# ATSAML21E17B register map
Vendor: Atmel Corporation; Series: SAML21; File version: B
CPU: CM0+ r0p1, little endian, no MPU, no FPU, VTOR, 2 interrupt priority bits
Registers are 32-bit, read-write, reset 0x0 unless marked. A register's access mark holds for its fields unless they carry their own. Offsets are from the block's base; [hi:lo] are bit positions; {n}, {i} and the like mark numbered series; 'fields as' and 'values as' point back to an identical list.

## CCL — Configurable Custom Logic
Base 0x43001C00; register names take the prefix CCL_
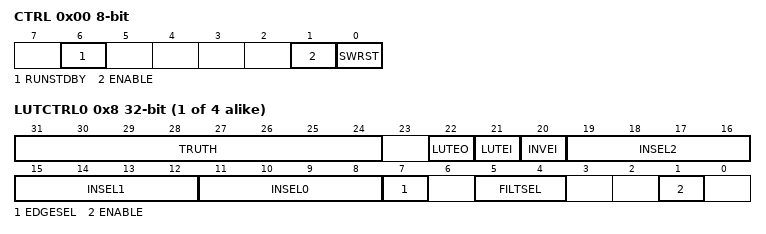
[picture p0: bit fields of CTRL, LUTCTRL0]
0x00 CTRL 8-bit — Control
  [6] RUNSTDBY — Run during Standby
  [1] ENABLE
  [0] SWRST wo — Software Reset
{0x4+i} SEQCTRL{i} (i=0..1) 8-bit — SEQ Control x
  [3:0] SEQSEL — Sequential Selection
    0=DISABLE (Sequential logic is disabled); 1=DFF (D flip flop); 2=JK (JK flip flop); 3=LATCH (D latch); 4=RS (RS latch)
{0x8+4i} LUTCTRL{i} (i=0..3) — LUT Control x
  [31:24] TRUTH — Truth Value
  [22] LUTEO — Event Output Enable
  [21] LUTEI — Event Input Enable
  [20] INVEI — Input Event Invert
  [19:16] INSEL2 — Input Selection 2
  [15:12] INSEL1 — Input Selection 1
  [11:8] INSEL0 — Input Selection 0
    0=MASK (Masked input); 1=FEEDBACK (Feedback input source); 2=LINK (Linked LUT input source); 3=EVENT (Event in put source); 4=IO (I/O pin input source); 5=AC (AC input source); 6=TC (TC input source); 7=ALTTC (Alternate TC input source); 8=TCC (TCC input source); 9=SERCOM (SERCOM inout source)
  [7] EDGESEL — Edge Selection
  [5:4] FILTSEL — Filter Selection
    0=DISABLE (Filter disabled); 1=SYNCH (Synchronizer enabled); 2=FILTER (Filter enabled)
  [1] ENABLE — LUT Enable

## DAC — Digital-to-Analog Converter
Base 0x42003000; register names take the prefix DAC_
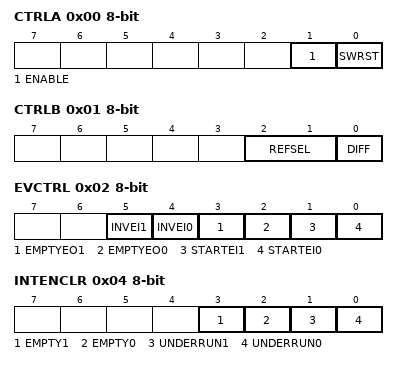
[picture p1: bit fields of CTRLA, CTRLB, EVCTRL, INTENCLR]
0x00 CTRLA 8-bit — Control A
  [1] ENABLE — Enable DAC Controller
  [0] SWRST — Software Reset
0x01 CTRLB 8-bit — Control B
  [2:1] REFSEL — Reference Selection for DAC0/1
    0=VREFPU (External reference unbuffered); 1=VDDANA (Analog supply); 2=VREFPB (External reference buffered); 3=INTREF (Internal bandgap reference)
  [0] DIFF — Differential mode enable
0x02 EVCTRL 8-bit — Event Control
  [5] INVEI1 — Enable Invertion of DAC 1 input event
  [4] INVEI0 — Enable Invertion of DAC 0 input event
  [3] EMPTYEO1 — Data Buffer Empty Event Output DAC 1
  [2] EMPTYEO0 — Data Buffer Empty Event Output DAC 0
  [1] STARTEI1 — Start Conversion Event Input DAC 1
  [0] STARTEI0 — Start Conversion Event Input DAC 0
0x04 INTENCLR 8-bit — Interrupt Enable Clear
  [3] EMPTY1 — Data Buffer 1 Empty Interrupt Enable
  [2] EMPTY0 — Data Buffer 0 Empty Interrupt Enable
  [1] UNDERRUN1 — Underrun Interrupt Enable for DAC 1
  [0] UNDERRUN0 — Underrun Interrupt Enable for DAC 0
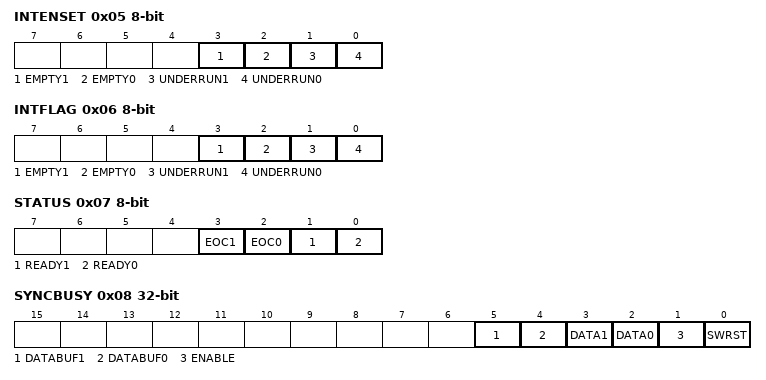
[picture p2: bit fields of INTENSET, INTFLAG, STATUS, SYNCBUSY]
0x05 INTENSET 8-bit — Interrupt Enable Set
  fields as INTENCLR
0x06 INTFLAG 8-bit — Interrupt Flag Status and Clear
  [3] EMPTY1 — Data Buffer 1 Empty
  [2] EMPTY0 — Data Buffer 0 Empty
  [1] UNDERRUN1 — DAC 1 Underrun
  [0] UNDERRUN0 — DAC 0 Underrun
0x07 STATUS 8-bit ro
  [3] EOC1 — DAC 1 End of Conversion
  [2] EOC0 — DAC 0 End of Conversion
  [1] READY1 — DAC 1 Startup Ready
  [0] READY0 — DAC 0 Startup Ready
0x08 SYNCBUSY ro — Synchronization Busy
  [5] DATABUF1 — Data Buffer DAC 1
  [4] DATABUF0 — Data Buffer DAC 0
  [3] DATA1 — Data DAC 1
  [2] DATA0 — Data DAC 0
  [1] ENABLE — DAC Enable Status
  [0] SWRST — Software Reset
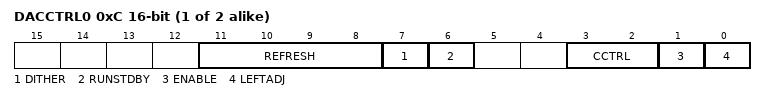
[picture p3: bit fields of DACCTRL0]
{0xC+2i} DACCTRL{i} (i=0..1) 16-bit — DAC n Control
  [11:8] REFRESH — Refresh period
  [7] DITHER — Dithering Mode
  [6] RUNSTDBY — Run in Standby
  [3:2] CCTRL — Current Control
    0=CC12M (1MHz<GCLK_DAC<12MHz); 1=CC1M (100kHz<GCLK_DAC<1MHz); 2=CC100K (10kHz<GCLK_DAC<100kHz); 3=CC10K (GCLK_DAC<100kHz)
  [1] ENABLE — Enable DAC0
  [0] LEFTADJ — Left Adjusted Data
{0x10+2i} DATA{i} (i=0..1) 16-bit wo — DAC n Data
  [15:0] DATA — DAC0 Data
{0x14+2i} DATABUF{i} (i=0..1) 16-bit wo — DAC n Data Buffer
  [15:0] DATABUF — DAC0 Data Buffer
0x18 DBGCTRL 8-bit — Debug Control
  [0] DBGRUN — Debug Run

## DSU — Device Service Unit
Base 0x41002000; register names take the prefix DSU_
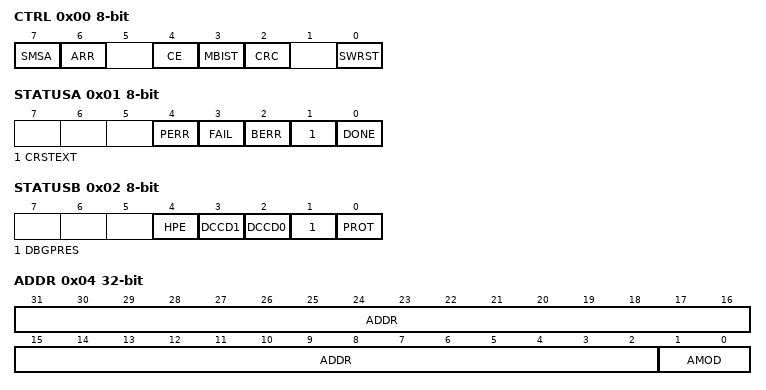
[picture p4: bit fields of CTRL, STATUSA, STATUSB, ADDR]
0x00 CTRL 8-bit wo — Control
  [7] SMSA — Start Memory Stream Access
  [6] ARR — Auxiliary Row Read
  [4] CE — Chip-Erase
  [3] MBIST — Memory built-in self-test
  [2] CRC — 32-bit Cyclic Redundancy Code
  [0] SWRST — Software Reset
0x01 STATUSA 8-bit
  [4] PERR — Protection Error
  [3] FAIL — Failure
  [2] BERR — Bus Error
  [1] CRSTEXT — CPU Reset Phase Extension
  [0] DONE
0x02 STATUSB 8-bit ro
  [4] HPE — Hot-Plugging Enable
  [3] DCCD1 — Debug Communication Channel 1 Dirty
  [2] DCCD0 — Debug Communication Channel 0 Dirty
  [1] DBGPRES — Debugger Present
  [0] PROT — Protected
0x04 ADDR — Address
  [31:2] ADDR — Address
  [1:0] AMOD — Access Mode
0x08 LENGTH
  [31:2] LENGTH
0x0C DATA
{0x10+4i} DCC{i} (i=0..1) — Debug Communication Channel n
  [31:0] DATA
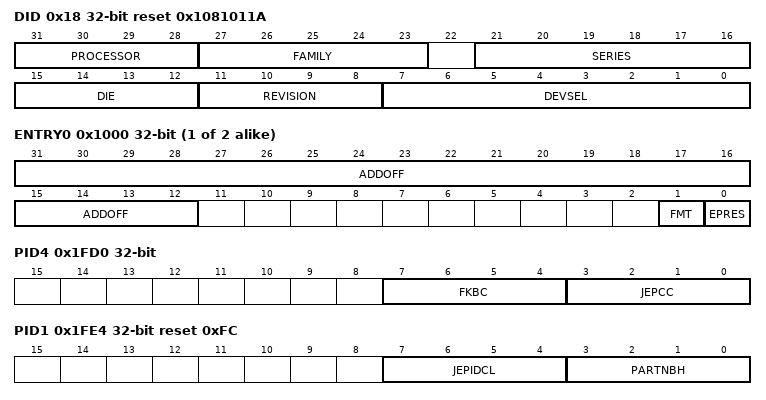
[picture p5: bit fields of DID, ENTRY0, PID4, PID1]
0x18 DID ro reset 0x1081011A — Device Identification
  [31:28] PROCESSOR
    0=Cortex-M0; 1=Cortex-M0+; 2=Cortex-M3; 3=Cortex-M4
  [27:23] FAMILY
    0=General purpose microcontroller; 1=PicoPower
  [21:16] SERIES
    0=Cortex-M0+ processor, basic feature set; 1=Cortex-M0+ processor, USB
  [15:12] DIE — Die Number
  [11:8] REVISION — Revision Number
  [7:0] DEVSEL — Device Select
{0xF0+4i} DCFG{i} (i=0..1) — Device Configuration
  [31:0] DCFG
{0x1000+4i} ENTRY{i} (i=0..1) ro — Coresight ROM Table Entry n
  [31:12] ADDOFF — Address Offset
  [1] FMT — Format
  [0] EPRES — Entry Present
0x1008 END ro — Coresight ROM Table End
  [31:0] END — End Marker
0x1FCC MEMTYPE ro — Coresight ROM Table Memory Type
  [0] SMEMP — System Memory Present
0x1FD0 PID4 ro — Peripheral Identification 4
  [7:4] FKBC — 4KB count
  [3:0] JEPCC — JEP-106 Continuation Code
{0x1FC0+4i} PID{i} ro (i=5..7) — Peripheral Identification {i}
0x1FE0 PID0 ro — Peripheral Identification 0
  [7:0] PARTNBL — Part Number Low
0x1FE4 PID1 ro reset 0xFC — Peripheral Identification 1
  [7:4] JEPIDCL — Low part of the JEP-106 Identity Code
  [3:0] PARTNBH — Part Number High
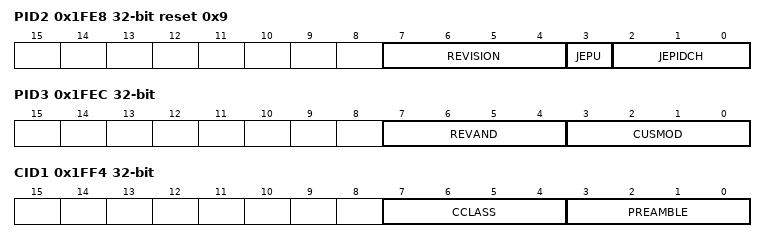
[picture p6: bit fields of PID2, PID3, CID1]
0x1FE8 PID2 ro reset 0x9 — Peripheral Identification 2
  [7:4] REVISION — Revision Number
  [3] JEPU — JEP-106 Identity Code is used
  [2:0] JEPIDCH — JEP-106 Identity Code High
0x1FEC PID3 ro — Peripheral Identification 3
  [7:4] REVAND — Revision Number
  [3:0] CUSMOD — ARM CUSMOD
0x1FF0 CID0 ro — Component Identification 0
  [7:0] PREAMBLEB0 — Preamble Byte 0
0x1FF4 CID1 ro — Component Identification 1
  [7:4] CCLASS — Component Class
  [3:0] PREAMBLE
0x1FF8 CID2 ro — Component Identification 2
  [7:0] PREAMBLEB2 — Preamble Byte 2
0x1FFC CID3 ro — Component Identification 3
  [7:0] PREAMBLEB3 — Preamble Byte 3

## Notices in the file
Atmel Microcontroller Software Support
Copyright (c) 2015, Atmel Corporation
All rights reserved.
Redistribution and use in source and binary forms, with or without
modification, are permitted provided that the following condition is met:
- Redistributions of source code must retain the above copyright notice,
this list of conditions and the disclaimer below.
Atmel's name may not be used to endorse or promote products derived from
this software without specific prior written permission.
DISCLAIMER: THIS SOFTWARE IS PROVIDED BY ATMEL "AS IS" AND ANY EXPRESS OR
IMPLIED WARRANTIES, INCLUDING, BUT NOT LIMITED TO, THE IMPLIED WARRANTIES OF
MERCHANTABILITY, FITNESS FOR A PARTICULAR PURPOSE AND NON-INFRINGEMENT ARE
DISCLAIMED. IN NO EVENT SHALL ATMEL BE LIABLE FOR ANY DIRECT, INDIRECT,
INCIDENTAL, SPECIAL, EXEMPLARY, OR CONSEQUENTIAL DAMAGES (INCLUDING, BUT NOT
LIMITED TO, PROCUREMENT OF SUBSTITUTE GOODS OR SERVICES; LOSS OF USE, DATA,
OR PROFITS; OR BUSINESS INTERRUPTION) HOWEVER CAUSED AND ON ANY THEORY OF
LIABILITY, WHETHER IN CONTRACT, STRICT LIABILITY, OR TORT (INCLUDING
NEGLIGENCE OR OTHERWISE) ARISING IN ANY WAY OUT OF THE USE OF THIS SOFTWARE,
EVEN IF ADVISED OF THE POSSIBILITY OF SUCH DAMAGE.
